# ATmega162 device description
Architecture: AVR8; Family: megaAVR
Registers are 8-bit, access not given, no defined reset value unless marked. A register's access mark holds for its fields unless they carry their own. Offsets are from the block's base; [hi:lo] are bit positions; 'fields as' and 'values as' point back to an identical list.

## CPU — CPU Registers
Instances: CPU 0x00
Parameters: CORE_VERSION=V2E
0x24 OSCCAL — Oscillator Calibration Value
  [7:0] OSCCAL — Oscillator Calibration
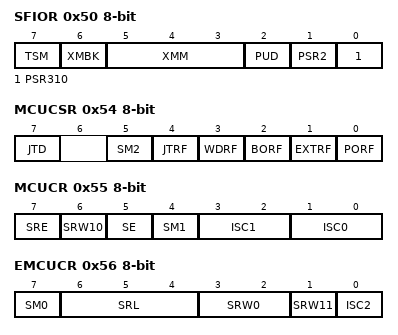
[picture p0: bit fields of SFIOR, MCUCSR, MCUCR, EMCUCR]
0x50 SFIOR — Special Function IO Register
  [7] TSM — Timer/Counter Synchronization Mode
  [6] XMBK — External Memory Bus Keeper Enable
  [5:3] XMM — External Memory High Mask Bits
  [2] PUD — Pull-up Disable
  [1] PSR2 — Prescaler Reset Timer/Counter2
  [0] PSR310 — Prescaler Reset Timer/Counter3, Timer/Counter1 and Timer/Counter0
0x54 MCUCSR — MCU Control And Status Register
  [7] JTD — JTAG Interface Disable
  [5] SM2 — Sleep Mode Select Bit 2
  [4] JTRF — JTAG Reset Flag
  [3] WDRF — Watchdog Reset Flag
  [2] BORF — Brown-out Reset Flag
  [1] EXTRF — External Reset Flag
  [0] PORF — Power-on reset flag
0x55 MCUCR — MCU Control Register
  [7] SRE — External SRAM Enable
  [6] SRW10 — External SRAM Wait State Select
  [5] SE — Sleep Enable
  [4] SM1 — Sleep Mode Select
  [3:2] ISC1 — Interrupt Sense Control 1 bits
    0=Low Level of INTX; 1=Any Logical Change in INTX; 2=Falling Edge of INTX; 3=Rising Edge of INTX
  [1:0] ISC0 — Interrupt Sense Control 0 bits
    values as ISC1
0x56 EMCUCR — Extended MCU Control Register
  [7] SM0 — Sleep mode Select Bit 0
  [6:4] SRL — Wait State Sector Limit Bits
    0=LS = N/A, US = 0x1100 - 0xFFFF; 1=LS = 0x1100 - 0x1FFF, US = 0x2000 - 0xFFFF; 2=LS = 0x1100 - 0x3FFF, US = 0x4000 - 0xFFFF; 3=LS = 0x1100 - 0x5FFF, US = 0x6000 - 0xFFFF; 4=LS = 0x1100 - 0x7FFF, US = 0x8000 - 0xFFFF; 5=LS = 0x1100 - 0x9FFF, US = 0xA000 - 0xFFFF; 6=LS = 0x1100 - 0xBFFF, US = 0xC000 - 0xFFFF; 7=LS = 0x1100 - 0xDFFF, US = 0xE000 - 0xFFFF
  [3:2] SRW0 — Wait State Select Bit 1 for Lower Sector
    0=No wait-states; 1=Wait one cycle during read/write strobe; 2=Wait two cycles during read/write strobe; 3=Wait two cycles during read/write and wait one cycle before driving out new address
  [1] SRW11 — Wait State Select Bit 1 for Upper Sector
  [0] ISC2 — Interrupt Sense Control 2
0x5D SP 16-bit — Stack Pointer
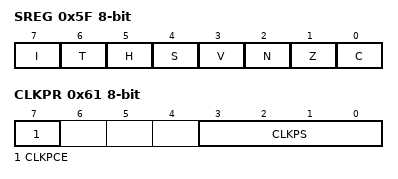
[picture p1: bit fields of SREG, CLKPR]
0x5F SREG — Status Register
  [7] I — Global Interrupt Enable
  [6] T — Bit Copy Storage
  [5] H — Half Carry Flag
  [4] S — Sign Bit
  [3] V — Two's Complement Overflow Flag
  [2] N — Negative Flag
  [1] Z — Zero Flag
  [0] C — Carry Flag
0x61 CLKPR — Clock prescale register
  [7] CLKPCE — Clock Prescaler Change Enable
  [3:0] CLKPS — Clock Prescaler Select Bits
    0=1; 1=2; 2=4; 3=8; 4=16; 5=32; 6=64; 7=128; 8=256
Value list OSCCAL_VALUE_ADDRESSES: 0=8_0_MHz

## JTAG — JTAG Interface
Instances: JTAG 0x00
0x24 OCDR — On-Chip Debug Related Register in I/O Memory
  [7:0] OCDR — On-Chip Debug Register Bits
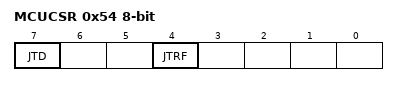
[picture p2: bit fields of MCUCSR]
0x54 MCUCSR — MCU Control And Status Register
  [7] JTD — JTAG Interface Disable
  [4] JTRF — JTAG Reset Flag

## BOOT_LOAD — Bootloader
Instances: BOOT_LOAD 0x00
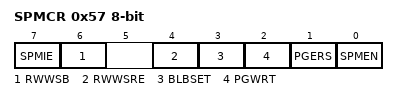
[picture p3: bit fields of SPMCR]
0x57 SPMCR — Store Program Memory Control Register
  [7] SPMIE — SPM Interrupt Enable
  [6] RWWSB — Read While Write Section Busy
  [4] RWWSRE — Read While Write secion read enable
  [3] BLBSET — Boot Lock Bit Set
  [2] PGWRT — Page Write
  [1] PGERS — Page Erase
  [0] SPMEN — Store Program Memory Enable

## EEPROM
Instances: EEPROM 0x00
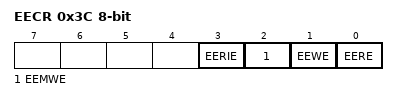
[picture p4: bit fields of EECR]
0x3C EECR — EEPROM Control Register
  [3] EERIE — EEPROM Ready Interrupt Enable
  [2] EEMWE — EEPROM Master Write Enable
  [1] EEWE — EEPROM Write Enable
  [0] EERE — EEPROM Read Enable
0x3D EEDR — EEPROM Data Register
  [7:0] EEDR — EEPROM Data Register bits
0x3E EEAR 16-bit — EEPROM Address Register Bytes
  [8:0] EEAR — EEPROM Address Register bits

## PORTA — I/O Port
Instances: PORTA 0x00
0x39 PINA — Port A Input Pins
0x3A DDRA — Port A Data Direction Register
0x3B PORTA — Port A Data Register

## PORTB — I/O Port
Instances: PORTB 0x00
0x36 PINB — Port B Input Pins
0x37 DDRB — Port B Data Direction Register
0x38 PORTB — Port B Data Register

## PORTC — I/O Port
Instances: PORTC 0x00
0x33 PINC — Port C Input Pins
0x34 DDRC — Port C Data Direction Register
0x35 PORTC — Port C Data Register

## PORTD — I/O Port
Instances: PORTD 0x00
0x30 PIND — Port D Input Pins
0x31 DDRD — Port D Data Direction Register
0x32 PORTD — Port D Data Register

## PORTE — I/O Port
Instances: PORTE 0x00
0x25 PINE bits used 3:0 — Input Pins, Port E
0x26 DDRE bits used 2:0 — Data Direction Register, Port E
0x27 PORTE bits used 2:0 — Data Register, Port E

## TC0 (TC8 module) — Timer/Counter, 8-bit
Instances: TC0 0x00
0x51 OCR0 — Timer/Counter 0 Output Compare Register
0x52 TCNT0 — Timer/Counter 0 Register
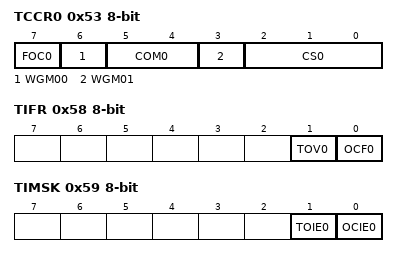
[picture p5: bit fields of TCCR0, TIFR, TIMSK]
0x53 TCCR0 — Timer/Counter 0 Control Register
  [7] FOC0 — Force Output Compare
  [6] WGM00 — Waveform Generation Mode 0
    0=Normal; 2=PWM, Phase Correct; 1=CTC; 3=Fast PWM
  [5:4] COM0 — Compare Match Output Modes
  [3] WGM01 — Waveform Generation Mode 1
  [2:0] CS0 — Clock Selects
    0=No Clock Source (Stopped); 1=Running, No Prescaling; 2=Running, CLK/8; 3=Running, CLK/64; 4=Running, CLK/256; 5=Running, CLK/1024; 6=Running, ExtClk Tx Falling Edge; 7=Running, ExtClk Tx Rising Edge
0x58 TIFR — Timer/Counter Interrupt Flag register
  [1] TOV0 — Timer/Counter0 Overflow Flag
  [0] OCF0 — Output Compare Flag 0
0x59 TIMSK — Timer/Counter Interrupt Mask Register
  [1] TOIE0 — Timer/Counter0 Overflow Interrupt Enable
  [0] OCIE0 — Timer/Counter0 Output Compare Match Interrupt register

## WDT — Watchdog Timer
Instances: WDT 0x00
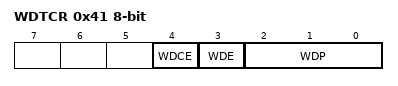
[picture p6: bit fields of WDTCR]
0x41 WDTCR — Watchdog Timer Control Register
  [4] WDCE — Watchdog Change Enable
  [3] WDE — Watch Dog Enable
  [2:0] WDP — Watch Dog Timer Prescaler bits
    0=Oscillator Cycles 16K; 1=Oscillator Cycles 32K; 2=Oscillator Cycles 64K; 3=Oscillator Cycles 128K; 4=Oscillator Cycles 256K; 5=Oscillator Cycles 512K; 6=Oscillator Cycles 1024K; 7=Oscillator Cycles 2048K

## EXINT — External Interrupts
Instances: EXINT 0x00
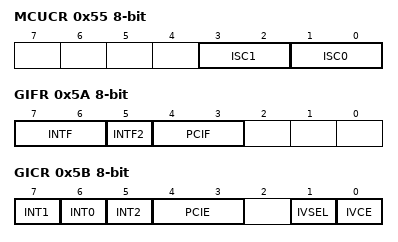
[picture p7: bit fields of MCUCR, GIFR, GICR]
0x55 MCUCR — MCU Control Register
  [3:2] ISC1 — Interrupt Sense Control 1 Bits
    0=Low Level of INTX; 1=Any Logical Change of INTX; 2=Falling Edge of INTX; 3=Rising Edge of INTX
  [1:0] ISC0 — Interrupt Sense Control 0 Bits
    values as ISC1
0x56 EMCUCR — Extended MCU Control Register
  [0] ISC2 — Interrupt Sense Control 2
0x5A GIFR — General Interrupt Flag Register
  [7:6] INTF — External Interrupt Flags
  [5] INTF2 — External Interrupt Flag 2
  [4:3] PCIF — Pin Change Interrupt Flags
0x5B GICR — General Interrupt Control Register
  [7] INT1 — External Interrupt Request 1 Enable
  [6] INT0 — External Interrupt Request 0 Enable
  [5] INT2 — External Interrupt Request 2 Enable
  [4:3] PCIE — Pin Change Interrupt Enables
  [1] IVSEL — Interrupt Vector Select
  [0] IVCE — Interrupt Vector Change Enable
0x6B PCMSK0 — Pin Change Enable Mask
  [7:0] PCINT — Pin Change Interrupt mask bits
0x6C PCMSK1 — Pin Change Mask Register 1
  [7:0] PCINT (bit 8 of the value upward) — Pin Change Interrupt mask bits
